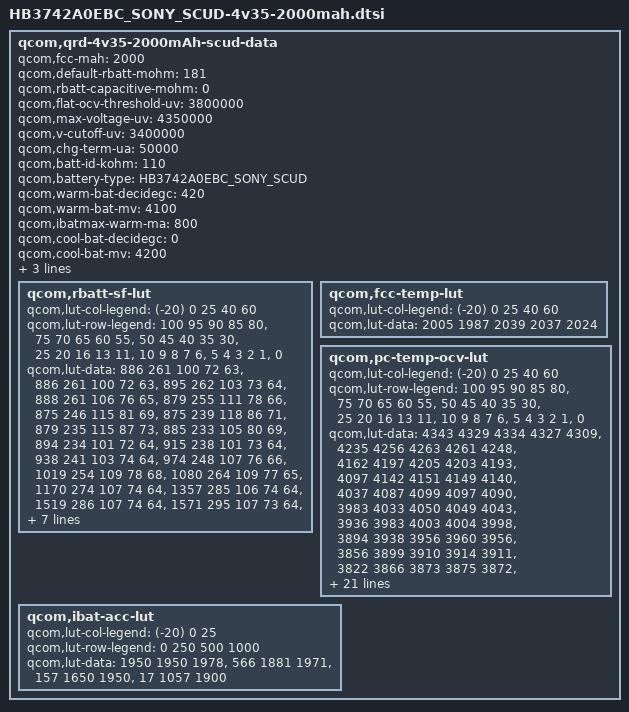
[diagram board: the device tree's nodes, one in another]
/* Copyright (c) 2013, The Linux Foundation. All rights reserved.
 *
 * This program is free software; you can redistribute it and/or modify
 * it under the terms of the GNU General Public License version 2 and
 * only version 2 as published by the Free Software Foundation.
 *
 * This program is distributed in the hope that it will be useful,
 * but WITHOUT ANY WARRANTY; without even the implied warranty of
 * MERCHANTABILITY or FITNESS FOR A PARTICULAR PURPOSE.  See the
 * GNU General Public License for more details.
 */

qcom,qrd-4v35-2000mAh-scud-data {
	qcom,fcc-mah = <2000>;
	qcom,default-rbatt-mohm = <181>;
	qcom,rbatt-capacitive-mohm = <0>;
	qcom,flat-ocv-threshold-uv = <3800000>;
	qcom,max-voltage-uv = <4350000>;
	qcom,v-cutoff-uv = <3400000>;
	qcom,chg-term-ua = <50000>;
	qcom,batt-id-kohm = <110>;
	qcom,battery-type = "HB3742A0EBC_SONY_SCUD";

	qcom,warm-bat-decidegc = <420>;
	qcom,warm-bat-mv = <4100>;
	qcom,ibatmax-warm-ma = <800>;

	qcom,cool-bat-decidegc = <0>;
	qcom,cool-bat-mv = <4200>;
	qcom,ibatmax-cool-ma = <0>;

	qcom,hot-bat-decidegc = <520>;
	qcom,cold-bat-decidegc = <0>;

	qcom,rbatt-sf-lut {
		qcom,lut-col-legend = <(-20) 0 25 40 60>;
		qcom,lut-row-legend = <100 95 90 85 80>,
				<75 70 65 60 55>,
				<50 45 40 35 30>,
				<25 20 16 13 11>,
				<10 9 8 7 6>,
				<5 4 3 2 1>,
				<0>;
		qcom,lut-data = <886 261 100 72 63>,
				<886 261 100 72 63>,
				<895 262 103 73 64>,
				<888 261 106 76 65>,
				<879 255 111 78 66>,
				<875 246 115 81 69>,
				<875 239 118 86 71>,
				<879 235 115 87 73>,
				<885 233 105 80 69>,
				<894 234 101 72 64>,
				<915 238 101 73 64>,
				<938 241 103 74 64>,
				<974 248 107 76 66>,
				<1019 254 109 78 68>,
				<1080 264 109 77 65>,
				<1170 274 107 74 64>,
				<1357 285 106 74 64>,
				<1519 286 107 74 64>,
				<1571 295 107 73 64>,
				<1462 303 106 74 64>,
				<1281 297 107 75 64>,
				<1400 286 109 75 65>,
				<1575 294 112 77 66>,
				<1807 306 114 76 65>,
				<2143 314 113 76 65>,
				<2620 324 114 76 66>,
				<3366 344 117 77 67>,
				<4734 380 125 81 72>,
				<7388 439 135 87 89>,
				<13148 644 176 126 1425>,
				<21052 13234 10392 25998 19317>;
	};

	qcom,fcc-temp-lut {
		qcom,lut-col-legend = <(-20) 0 25 40 60>;
		qcom,lut-data = <2005 1987 2039 2037 2024>;
	};

	qcom,pc-temp-ocv-lut {
		qcom,lut-col-legend = <(-20) 0 25 40 60>;
		qcom,lut-row-legend = <100 95 90 85 80>,
				<75 70 65 60 55>,
				<50 45 40 35 30>,
				<25 20 16 13 11>,
				<10 9 8 7 6>,
				<5 4 3 2 1>,
				<0>;
		qcom,lut-data = <4343 4329 4334 4327 4309>,
				<4235 4256 4263 4261 4248>,
				<4162 4197 4205 4203 4193>,
				<4097 4142 4151 4149 4140>,
				<4037 4087 4099 4097 4090>,
				<3983 4033 4050 4049 4043>,
				<3936 3983 4003 4004 3998>,
				<3894 3938 3956 3960 3956>,
				<3856 3899 3910 3914 3911>,
				<3822 3866 3873 3875 3872>,
				<3795 3837 3844 3846 3844>,
				<3771 3812 3820 3823 3821>,
				<3750 3791 3800 3803 3801>,
				<3731 3773 3782 3786 3783>,
				<3713 3759 3765 3765 3757>,
				<3695 3744 3746 3741 3729>,
				<3675 3723 3724 3720 3707>,
				<3657 3699 3701 3698 3685>,
				<3637 3681 3680 3679 3668>,
				<3621 3669 3671 3672 3662>,
				<3612 3664 3668 3669 3659>,
				<3599 3658 3663 3665 3655>,
				<3584 3651 3656 3659 3646>,
				<3565 3640 3642 3645 3625>,
				<3542 3621 3616 3616 3589>,
				<3511 3588 3573 3573 3543>,
				<3470 3539 3518 3518 3485>,
				<3415 3476 3447 3447 3409>,
				<3339 3391 3349 3349 3308>,
				<3222 3261 3197 3195 3174>,
				<3000 3000 3000 3000 3000>;
	};

	qcom,ibat-acc-lut {
		qcom,lut-col-legend = <(-20) 0 25>;
		qcom,lut-row-legend = <0 250 500 1000>;
		qcom,lut-data = <1950 1950 1978>,
				<566 1881 1971>,
				<157 1650 1950>,
				<17 1057 1900>;
	};
};
